# PIC32CM5112SG00100 register map
Vendor: Microchip Technology; Series: PIC32CMSG00; File version: 0
CPU: CM23 r0p0, little endian, MPU, no FPU, 2 interrupt priority bits, 141 interrupts, 13 SAU regions
Registers are 32-bit, read-write, reset 0x0 unless marked. A register's access mark holds for its fields unless they carry their own. Offsets are from the block's base; [hi:lo] are bit positions; {n}, {i} and the like mark numbered series; <NAME> marks a mode.

## FREQM — Frequency Meter
Base 0x4400C000
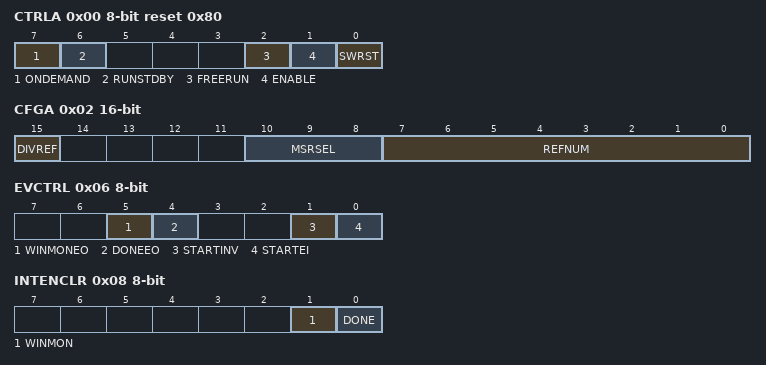
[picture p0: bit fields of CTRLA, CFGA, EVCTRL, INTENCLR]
0x00 CTRLA 8-bit reset 0x80 — Control A Register
  [7] ONDEMAND — On Demand Control
  [6] RUNSTDBY — Run In Standby
  [2] FREERUN — Free Running Mode
  [1] ENABLE
  [0] SWRST — Software Reset
0x01 CTRLB 8-bit wo — Control B Register
  [0] START — Start Measurement
0x02 CFGA 16-bit — Config A Register
  [15] DIVREF — Divide Reference Clock
    0=DIV1 (The reference clock is divided by 1); 1=DIV8 (The reference clock is divided by 8)
  [10:8] MSRSEL — Measurement Clock Selection
    0=GCLK (GCLK Input Clock); 1=CPU (CPU Input Clock)
  [7:0] REFNUM — Number of Reference Clock Cycles
0x04 CTRLC 8-bit — Control C Register
  [2:0] WINMODE — Window Monitor Mode
    0=DISABLE (No window mode (default)); 1=MODE1 (VALUE > WINLT); 2=MODE2 (VALUE < WINUT); 3=MODE3 (WINLT < VALUE < WINUT); 4=MODE4 (!(WINLT < VALUE < WINUT))
0x06 EVCTRL 8-bit — Event Control Register
  [5] WINMONEO — Window Monitor Event Out
  [4] DONEEO — Measurement Done Event Out
  [1] STARTINV — Start Measurement Event Invert Enable
  [0] STARTEI — Start Measurement Event Input Enable
0x08 INTENCLR 8-bit write-1-clears — Interrupt Enable Clear Register
  [1] WINMON — Window Monitor Interrupt Disable
  [0] DONE — Measurement Done Interrupt Disable
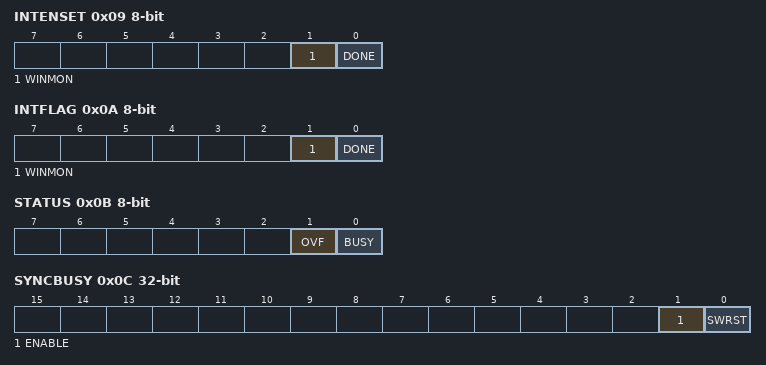
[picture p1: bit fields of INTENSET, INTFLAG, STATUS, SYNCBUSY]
0x09 INTENSET 8-bit write-1-sets — Interrupt Enable Set Register
  [1] WINMON — Window Monitor Interrupt Enable
  [0] DONE — Measurement Done Interrupt Enable
0x0A INTFLAG 8-bit write-1-clears — Interrupt Flag Register
  [1] WINMON — Window Monitor
  [0] DONE — Measurement Done
0x0B STATUS 8-bit
  [1] OVF — Sticky Count Value Overflow
  [0] BUSY — FREQM Status
0x0C SYNCBUSY ro — Synchronization Busy Register
  [1] ENABLE
  [0] SWRST — Software Reset
0x10 VALUE ro — Count Value Register
  [23:0] VALUE — Measurement Value
0x20 WINLT — Window Monitor Lower Threshold
  [23:0] WINLT — Window Lower Threshold
0x24 WINUT — Window Monitor Upper Threshold
  [23:0] WINUT — Window Upper Threshold

## GCLK — Generic Clock Generator
Base 0x44008000
0x00 CTRLA 8-bit — Control
  [0] SWRST — Software Reset
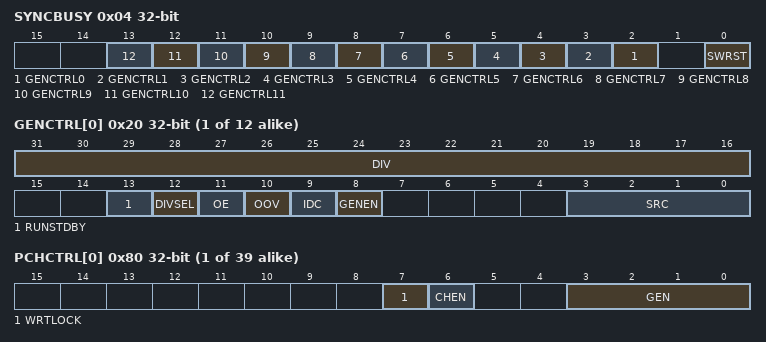
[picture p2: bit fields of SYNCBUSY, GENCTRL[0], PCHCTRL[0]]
0x04 SYNCBUSY ro — Synchronization Busy
  [n+2] GENCTRL{n} (n=0..11) — Generic Clock Generator Control {n} Synchronization Busy bit
  [0] SWRST — Software Reset Synchronization Busy bit
{0x20+4i} GENCTRL[{i}] (i=0..11) — Generic Clock Generator Control
  [31:16] DIV — Division Factor
  [13] RUNSTDBY — Run in Standby
  [12] DIVSEL — Divide Selection
    0=DIV1 (Divide input directly by divider factor); 1=DIV2 (Divide input by 2^(divider factor+ 1))
  [11] OE — Output Enable
  [10] OOV — Output Off Value
  [9] IDC — Improve Duty Cycle
  [8] GENEN — Generic Clock Generator Enable
  [3:0] SRC — Source Select
    0=XOSC (XOSC oscillator output); 1=GCLK_IN (Generator input pad (GCLK_IO)); 2=GCLK_GEN1 (Generic clock generator 1 output); 3=OSCULP32K (OSCULP32K oscillator output); 4=XOSC32K (XOSC32K oscillator output); 5=DFLL48M (DFLL oscillator output); {v}=PLL0_CLKOUT{v-5} (PLL 0 port CLKOUT{v-5}) (v=6..10)
{0x80+4i} PCHCTRL[{i}] (i=0..38) — Peripheral Clock Control
  [7] WRTLOCK — Write Lock
  [6] CHEN — Channel Enable
  [3:0] GEN — Generic Clock Generator
    {v}=GCLK{v} (Generic clock generator {v}) (v=0..11)

## H2PB0 — AHB To APB Bridge
Base 0x44032000; register names take the prefix H2PB_
Same registers: H2PB1 0x44838000, H2PB2 0x4500E000
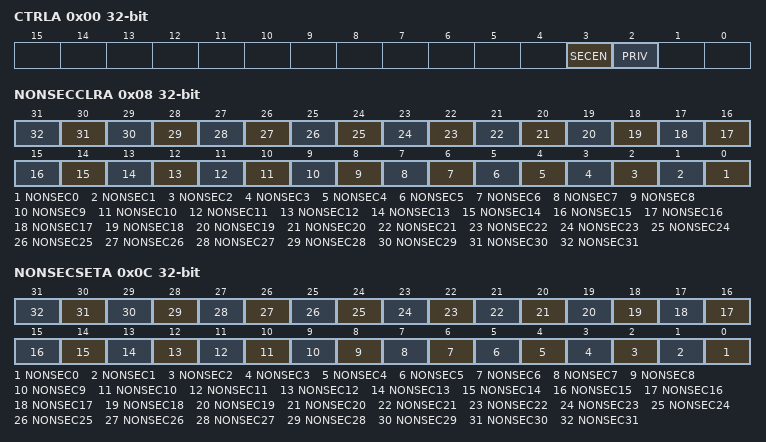
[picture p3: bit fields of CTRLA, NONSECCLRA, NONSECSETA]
0x00 CTRLA — H2PB CONTROL Register
  [3] SECEN — SECEN security enable bit
  [2] PRIV — PRIV privileged access protection bit
0x08 NONSECCLRA write-1-clears — Non-Security Clear Register A
  [n] NONSEC{n} (n=0..31) — non-security bit for APB Slave k, k=0..31
0x0C NONSECSETA write-1-sets — Non-Security SET Register A
  [n] NONSEC{n} (n=0..31) — non-security bit for APB Slave k, k=0..31
